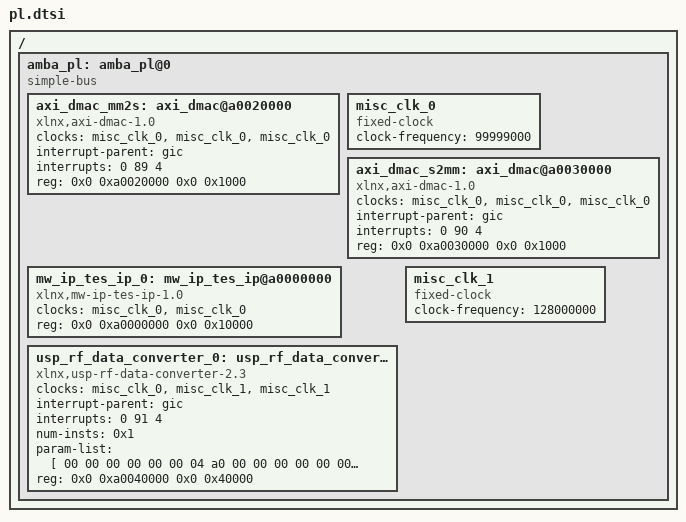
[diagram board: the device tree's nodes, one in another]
/*
 * CAUTION: This file is automatically generated by Xilinx.
 * Version:  
 * Today is: Thu Aug 13 04:19:24 2020
 */


/ {
	amba_pl: amba_pl@0 {
		#address-cells = <2>;
		#size-cells = <2>;
		compatible = "simple-bus";
		ranges ;
		axi_dmac_mm2s: axi_dmac@a0020000 {
			clock-names = "s_axi_aclk", "m_src_axi_aclk", "m_axis_aclk";
			clocks = <&misc_clk_0>, <&misc_clk_0>, <&misc_clk_0>;
			compatible = "xlnx,axi-dmac-1.0";
			interrupt-names = "irq";
			interrupt-parent = <&gic>;
			interrupts = <0 89 4>;
			reg = <0x0 0xa0020000 0x0 0x1000>;
		};
		misc_clk_0: misc_clk_0 {
			#clock-cells = <0>;
			clock-frequency = <99999000>;
			compatible = "fixed-clock";
		};
		axi_dmac_s2mm: axi_dmac@a0030000 {
			clock-names = "s_axi_aclk", "m_dest_axi_aclk", "s_axis_aclk";
			clocks = <&misc_clk_0>, <&misc_clk_0>, <&misc_clk_0>;
			compatible = "xlnx,axi-dmac-1.0";
			interrupt-names = "irq";
			interrupt-parent = <&gic>;
			interrupts = <0 90 4>;
			reg = <0x0 0xa0030000 0x0 0x1000>;
		};
		mw_ip_tes_ip_0: mw_ip_tes_ip@a0000000 {
			clock-names = "IPCORE_CLK", "AXI4_ACLK";
			clocks = <&misc_clk_0>, <&misc_clk_0>;
			compatible = "xlnx,mw-ip-tes-ip-1.0";
			reg = <0x0 0xa0000000 0x0 0x10000>;
		};
		usp_rf_data_converter_0: usp_rf_data_converter@a0040000 {
			clock-names = "s_axi_aclk", "m0_axis_aclk", "s0_axis_aclk";
			clocks = <&misc_clk_0>, <&misc_clk_1>, <&misc_clk_1>;
			compatible = "xlnx,usp-rf-data-converter-2.3";
			interrupt-names = "irq";
			interrupt-parent = <&gic>;
			interrupts = <0 91 4>;
			num-insts = <0x1>;
			param-list = [ 00 00 00 00 00 00 04 a0 00 00 00 00 00 00 00 00 00 00 00 00 00 00 00 00 01 00 00 00 01 00 00 00 02 00 00 00 00 00 00 00 01 00 00 00 01 00 00 00 fc a9 f1 d2 4d 62 00 40 00 00 00 00 00 00 60 40 00 00 00 00 00 00 60 40 40 00 00 00 04 00 00 00 01 00 00 00 00 00 00 00 00 00 00 00 00 00 1c 40 04 00 00 00 01 00 00 00 00 00 00 00 02 00 00 00 00 00 00 00 00 00 00 00 00 00 00 00 02 00 00 00 00 00 00 00 00 00 00 00 00 00 00 00 02 00 00 00 00 00 00 00 00 00 00 00 00 00 00 00 02 00 00 00 00 00 00 00 00 00 00 00 04 00 00 00 04 00 00 00 00 00 00 00 00 00 00 00 01 00 00 00 00 00 00 00 10 00 00 00 00 00 00 00 00 00 00 00 00 00 00 00 03 00 00 00 00 00 00 00 10 00 00 00 00 00 00 00 00 00 00 00 00 00 00 00 03 00 00 00 00 00 00 00 10 00 00 00 00 00 00 00 00 00 00 00 00 00 00 00 03 00 00 00 00 00 00 00 00 00 00 00 9a 99 99 99 99 99 19 40 00 00 00 00 00 00 b9 40 00 00 00 00 00 00 00 00 0a 00 00 00 02 00 00 00 01 00 00 00 00 00 00 00 00 00 00 00 00 00 24 40 04 00 00 00 00 00 00 00 00 00 00 00 02 00 00 00 00 00 00 00 00 00 00 00 00 00 00 00 02 00 00 00 00 00 00 00 00 00 00 00 00 00 00 00 02 00 00 00 00 00 00 00 00 00 00 00 00 00 00 00 02 00 00 00 00 00 00 00 00 00 00 00 10 00 00 00 00 00 00 00 00 00 00 00 00 00 00 00 03 00 00 00 00 00 00 00 10 00 00 00 00 00 00 00 00 00 00 00 00 00 00 00 03 00 00 00 00 00 00 00 10 00 00 00 00 00 00 00 00 00 00 00 00 00 00 00 03 00 00 00 00 00 00 00 10 00 00 00 00 00 00 00 00 00 00 00 00 00 00 00 03 00 00 00 00 00 00 00 00 00 00 00 9a 99 99 99 99 99 19 40 00 00 00 00 00 00 b9 40 00 00 00 00 00 00 00 00 0a 00 00 00 02 00 00 00 01 00 00 00 00 00 00 00 00 00 00 00 00 00 24 40 04 00 00 00 00 00 00 00 00 00 00 00 02 00 00 00 00 00 00 00 00 00 00 00 00 00 00 00 02 00 00 00 00 00 00 00 00 00 00 00 00 00 00 00 02 00 00 00 00 00 00 00 00 00 00 00 00 00 00 00 02 00 00 00 00 00 00 00 00 00 00 00 10 00 00 00 00 00 00 00 00 00 00 00 00 00 00 00 03 00 00 00 00 00 00 00 10 00 00 00 00 00 00 00 00 00 00 00 00 00 00 00 03 00 00 00 00 00 00 00 10 00 00 00 00 00 00 00 00 00 00 00 00 00 00 00 03 00 00 00 00 00 00 00 10 00 00 00 00 00 00 00 00 00 00 00 00 00 00 00 03 00 00 00 00 00 00 00 00 00 00 00 9a 99 99 99 99 99 19 40 00 00 00 00 00 00 b9 40 00 00 00 00 00 00 00 00 0a 00 00 00 02 00 00 00 01 00 00 00 00 00 00 00 00 00 00 00 00 00 24 40 04 00 00 00 00 00 00 00 00 00 00 00 02 00 00 00 00 00 00 00 00 00 00 00 00 00 00 00 02 00 00 00 00 00 00 00 00 00 00 00 00 00 00 00 02 00 00 00 00 00 00 00 00 00 00 00 00 00 00 00 02 00 00 00 00 00 00 00 00 00 00 00 10 00 00 00 00 00 00 00 00 00 00 00 00 00 00 00 03 00 00 00 00 00 00 00 10 00 00 00 00 00 00 00 00 00 00 00 00 00 00 00 03 00 00 00 00 00 00 00 10 00 00 00 00 00 00 00 00 00 00 00 00 00 00 00 03 00 00 00 00 00 00 00 10 00 00 00 00 00 00 00 00 00 00 00 00 00 00 00 03 00 00 00 01 00 00 00 01 00 00 00 fc a9 f1 d2 4d 62 00 40 b8 1e 85 eb 51 b8 6e 40 00 00 00 00 00 00 60 40 32 00 00 00 06 00 00 00 01 00 00 00 00 00 00 00 00 00 00 00 00 00 04 40 04 00 00 00 01 00 00 00 02 00 00 00 00 00 00 00 02 00 00 00 00 00 00 00 02 00 00 00 00 00 00 00 02 00 00 00 00 00 00 00 04 00 00 00 04 00 00 00 00 00 00 00 01 00 00 00 00 00 00 00 08 00 00 00 00 00 00 00 00 00 00 00 03 00 00 00 00 00 00 00 08 00 00 00 00 00 00 00 00 00 00 00 03 00 00 00 00 00 00 00 08 00 00 00 00 00 00 00 00 00 00 00 03 00 00 00 00 00 00 00 00 00 00 00 00 00 00 00 00 00 00 40 00 00 00 00 00 40 9f 40 00 00 00 00 00 00 00 00 0a 00 00 00 01 00 00 00 01 00 00 00 00 00 00 00 00 00 00 00 00 00 04 40 04 00 00 00 00 00 00 00 02 00 00 00 00 00 00 00 02 00 00 00 00 00 00 00 02 00 00 00 00 00 00 00 02 00 00 00 00 00 00 00 08 00 00 00 00 00 00 00 00 00 00 00 03 00 00 00 00 00 00 00 08 00 00 00 00 00 00 00 00 00 00 00 03 00 00 00 00 00 00 00 08 00 00 00 00 00 00 00 00 00 00 00 03 00 00 00 00 00 00 00 08 00 00 00 00 00 00 00 00 00 00 00 03 00 00 00 00 00 00 00 00 00 00 00 00 00 00 00 00 00 00 40 00 00 00 00 00 40 9f 40 00 00 00 00 00 00 00 00 0a 00 00 00 01 00 00 00 01 00 00 00 00 00 00 00 00 00 00 00 00 00 04 40 04 00 00 00 00 00 00 00 02 00 00 00 00 00 00 00 02 00 00 00 00 00 00 00 02 00 00 00 00 00 00 00 02 00 00 00 00 00 00 00 08 00 00 00 00 00 00 00 00 00 00 00 03 00 00 00 00 00 00 00 08 00 00 00 00 00 00 00 00 00 00 00 03 00 00 00 00 00 00 00 08 00 00 00 00 00 00 00 00 00 00 00 03 00 00 00 00 00 00 00 08 00 00 00 00 00 00 00 00 00 00 00 03 00 00 00 00 00 00 00 00 00 00 00 00 00 00 00 00 00 00 40 00 00 00 00 00 40 9f 40 00 00 00 00 00 00 00 00 0a 00 00 00 01 00 00 00 01 00 00 00 00 00 00 00 00 00 00 00 00 00 04 40 04 00 00 00 00 00 00 00 02 00 00 00 00 00 00 00 02 00 00 00 00 00 00 00 02 00 00 00 00 00 00 00 02 00 00 00 00 00 00 00 08 00 00 00 00 00 00 00 00 00 00 00 03 00 00 00 00 00 00 00 08 00 00 00 00 00 00 00 00 00 00 00 03 00 00 00 00 00 00 00 08 00 00 00 00 00 00 00 00 00 00 00 03 00 00 00 00 00 00 00 08 00 00 00 00 00 00 00 00 00 00 00 03 00 00 00];
			reg = <0x0 0xa0040000 0x0 0x40000>;
		};
		misc_clk_1: misc_clk_1 {
			#clock-cells = <0>;
			clock-frequency = <128000000>;
			compatible = "fixed-clock";
		};
	};
};
